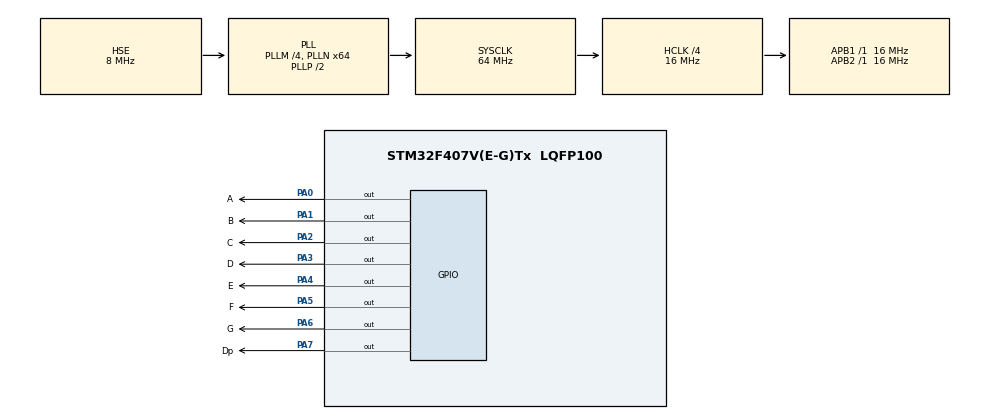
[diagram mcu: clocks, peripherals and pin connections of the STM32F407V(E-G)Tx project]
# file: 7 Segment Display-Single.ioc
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Mcu.Family=STM32F4
Mcu.Name=STM32F407V(E-G)Tx
Mcu.Package=LQFP100
NVIC.PriorityGroup=NVIC_PRIORITYGROUP_4
NVIC.TIM2_IRQn=true\:0\:0\:false\:false\:true\:true\:true
PA0-WKUP.GPIO_Label=A
PA0-WKUP.Signal=GPIO_Output
PA1.GPIO_Label=B
PA1.Signal=GPIO_Output
PA13.Mode=Serial_Wire
PA13.Signal=SYS_JTMS-SWDIO
PA14.Mode=Serial_Wire
PA14.Signal=SYS_JTCK-SWCLK
PA2.GPIO_Label=C
PA2.Signal=GPIO_Output
PA3.GPIO_Label=D
PA3.Signal=GPIO_Output
PA4.GPIO_Label=E
PA4.Signal=GPIO_Output
PA5.GPIO_Label=F
PA5.Signal=GPIO_Output
PA6.GPIO_Label=G
PA6.Signal=GPIO_Output
PA7.GPIO_Label=Dp
PA7.Signal=GPIO_Output
PH0-OSC_IN.Mode=HSE-External-Oscillator
PH0-OSC_IN.Signal=RCC_OSC_IN
PH1-OSC_OUT.Mode=HSE-External-Oscillator
PH1-OSC_OUT.Signal=RCC_OSC_OUT
ProjectManager.HeapSize=0x200
ProjectManager.StackSize=0x400
ProjectManager.TargetToolchain=STM32CubeIDE
RCC.48MHZClocksFreq_Value=32000000
RCC.AHBCLKDivider=RCC_SYSCLK_DIV4
RCC.AHBFreq_Value=16000000
RCC.APB1Freq_Value=16000000
RCC.APB1TimFreq_Value=16000000
RCC.APB2Freq_Value=16000000
RCC.APB2TimFreq_Value=16000000
RCC.CortexFreq_Value=16000000
RCC.HCLKFreq_Value=16000000
RCC.HSE_VALUE=8000000
RCC.HSI_VALUE=16000000
RCC.LSE_VALUE=32768
RCC.PLLM=4
RCC.PLLN=64
RCC.PLLSourceVirtual=RCC_PLLSOURCE_HSE
RCC.SYSCLKFreq_VALUE=64000000
RCC.SYSCLKSource=RCC_SYSCLKSOURCE_PLLCLK
RCC.VCOOutputFreq_Value=128000000
TIM2.Period=1000
TIM2.Prescaler=16000
TIM2.TIM_MasterOutputTrigger=TIM_TRGO_UPDATE
VP_TIM2_VS_ClockSourceINT.Mode=Internal
board=custom

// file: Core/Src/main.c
/* USER CODE BEGIN Header */
/**
 ******************************************************************************
 * @file           : main.c
 * @brief          : Main program body
 ******************************************************************************
 * @attention
 *
 * <h2><center>&copy; Copyright (c) 2021 STMicroelectronics.
 * All rights reserved.</center></h2>
 *
 * This software component is licensed by ST under BSD 3-Clause license,
 * the "License"; You may not use this file except in compliance with the
 * License. You may obtain a copy of the License at:
 *                        opensource.org/licenses/BSD-3-Clause
 *
 ******************************************************************************
 */
/* USER CODE END Header */

#include "main.h"
#include "tim.h"
#include "gpio.h"

/* USER CODE BEGIN PV */
uint8_t i;
////////For Common Anode////////
//uint8_t Segment_val_CA[11] = {0xC0, 0xF9, 0xA4, 0xB0, 0x99, 0x92, 0x82, 0xF8, 0x80, 0x90, 0x7F};

////////For Common Cathode////////
uint8_t Segment_val_CC[11] = {0x3F, 0x06, 0x5B, 0x4F, 0x66, 0x6D, 0x7D, 0x07, 0x7F, 0x6F, 0x80};
/* USER CODE END PV */

void SystemClock_Config(void);

int main(void)
{

	/* MCU Configuration--------------------------------------------------------*/

	/* Reset of all peripherals, Initializes the Flash interface and the Systick. */
	HAL_Init();

	/* Configure the system clock */
	SystemClock_Config();

	/* Initialize all configured peripherals */
	MX_GPIO_Init();
	MX_TIM2_Init();
	/* USER CODE BEGIN 2 */
	HAL_TIM_Base_Start_IT(&htim2);
	/* USER CODE END 2 */

	/* Infinite loop */
	while (1)
	{

	}
}

void SystemClock_Config(void)
{
	RCC_OscInitTypeDef RCC_OscInitStruct = {0};
	RCC_ClkInitTypeDef RCC_ClkInitStruct = {0};

	/** Configure the main internal regulator output voltage
	 */
	__HAL_RCC_PWR_CLK_ENABLE();
	__HAL_PWR_VOLTAGESCALING_CONFIG(PWR_REGULATOR_VOLTAGE_SCALE1);
	/** Initializes the CPU, AHB and APB busses clocks
	 */
	RCC_OscInitStruct.OscillatorType = RCC_OSCILLATORTYPE_HSE;
	RCC_OscInitStruct.HSEState = RCC_HSE_ON;
	RCC_OscInitStruct.PLL.PLLState = RCC_PLL_ON;
	RCC_OscInitStruct.PLL.PLLSource = RCC_PLLSOURCE_HSE;
	RCC_OscInitStruct.PLL.PLLM = 4;
	RCC_OscInitStruct.PLL.PLLN = 64;
	RCC_OscInitStruct.PLL.PLLP = RCC_PLLP_DIV2;
	RCC_OscInitStruct.PLL.PLLQ = 4;
	if (HAL_RCC_OscConfig(&RCC_OscInitStruct) != HAL_OK)
	{
		Error_Handler();
	}
	/** Initializes the CPU, AHB and APB busses clocks
	 */
	RCC_ClkInitStruct.ClockType = RCC_CLOCKTYPE_HCLK|RCC_CLOCKTYPE_SYSCLK
			|RCC_CLOCKTYPE_PCLK1|RCC_CLOCKTYPE_PCLK2;
	RCC_ClkInitStruct.SYSCLKSource = RCC_SYSCLKSOURCE_PLLCLK;
	RCC_ClkInitStruct.AHBCLKDivider = RCC_SYSCLK_DIV4;
	RCC_ClkInitStruct.APB1CLKDivider = RCC_HCLK_DIV1;
	RCC_ClkInitStruct.APB2CLKDivider = RCC_HCLK_DIV1;

	if (HAL_RCC_ClockConfig(&RCC_ClkInitStruct, FLASH_LATENCY_0) != HAL_OK)
	{
		Error_Handler();
	}
}

/* USER CODE BEGIN 4 */
void HAL_TIM_PeriodElapsedCallback(TIM_HandleTypeDef *htim)
{
	/* Prevent unused argument(s) compilation warning */
	UNUSED(htim);

	/* NOTE : This function should not be modified, when the callback is needed,
            the HAL_TIM_PeriodElapsedCallback could be implemented in the user file
	 */
	GPIOA->ODR = Segment_val_CC[i];
	i++;

	if(i == 11)
	{
		i = 0;
	}
}
/* USER CODE END 4 */

void Error_Handler(void)
{
}

/************************ (C) COPYRIGHT STMicroelectronics *****END OF FILE****/
